VERSION "Vinfast Single Pack DBC V0.1"

NS_ :

BS_:

BU_: BSS_SLAVE PACK
VAL_TABLE_ bms_rentalinfoPackType 2 "Pack D1" 1 "Pack E1" 0 "TBD" ;
VAL_TABLE_ bms_rentalinfoTBD1 2 "1.2kwh" 1 "1.9kwh" 0 "TBD" ;
VAL_TABLE_ bms_resultCheckScuSn 1 "PASS" 0 "FAIL" ;

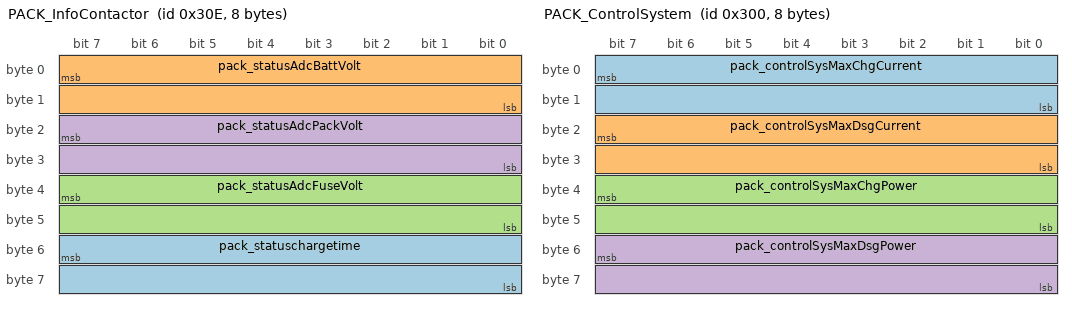
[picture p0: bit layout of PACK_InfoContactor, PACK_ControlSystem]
BO_ 782 PACK_InfoContactor: 8 PACK
 SG_ pack_statuschargetime : 55|16@0+ (1,0) [0|65535] ""  BSS_SLAVE
 SG_ pack_statusAdcBattVolt : 7|16@0+ (0.002,0) [0|131.07] "V"  BSS_SLAVE
 SG_ pack_statusAdcFuseVolt : 39|16@0+ (0.002,0) [0|131.07] "V"  BSS_SLAVE
 SG_ pack_statusAdcPackVolt : 23|16@0+ (0.002,0) [0|131.07] "V"  BSS_SLAVE

BO_ 2 PACK_ISO_Message: 8 PACK
 SG_ pack_iso_signal : 7|64@0+ (1,0) [0|1.84467440737096E+019] ""  BSS_SLAVE

BO_ 768 PACK_ControlSystem: 8 PACK
 SG_ pack_controlSysMaxChgCurrent : 7|16@0- (0.02,0) [-655|655] "A"  BSS_SLAVE
 SG_ pack_controlSysMaxDsgCurrent : 23|16@0- (0.02,0) [-655|655] "A"  BSS_SLAVE
 SG_ pack_controlSysMaxChgPower : 39|16@0- (1,0) [-32767|32767] "W"  BSS_SLAVE
 SG_ pack_controlSysMaxDsgPower : 55|16@0- (1,0) [-32767|32767] "W"  BSS_SLAVE

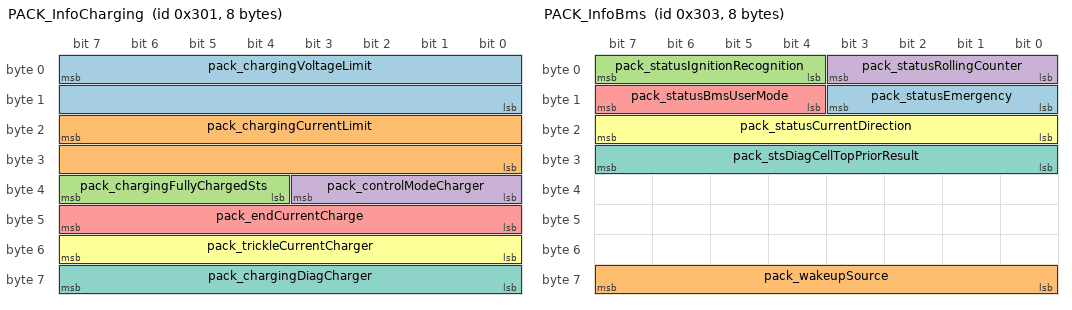
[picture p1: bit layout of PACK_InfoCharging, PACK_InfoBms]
BO_ 769 PACK_InfoCharging: 8 PACK
 SG_ pack_chargingVoltageLimit : 7|16@0+ (0.002,0) [0|131.07] "V"  BSS_SLAVE
 SG_ pack_chargingCurrentLimit : 23|16@0- (0.02,0) [-655|655] "A"  BSS_SLAVE
 SG_ pack_chargingFullyChargedSts : 39|4@0+ (1,0) [0|15] ""  BSS_SLAVE
 SG_ pack_controlModeCharger : 35|4@0+ (1,0) [0|15] ""  BSS_SLAVE
 SG_ pack_endCurrentCharge : 47|8@0+ (0.01,0) [0|2.55] "A"  BSS_SLAVE
 SG_ pack_trickleCurrentCharger : 55|8@0+ (0.01,0) [0|2.55] "A"  BSS_SLAVE
 SG_ pack_chargingDiagCharger : 63|8@0+ (1,0) [0|255] ""  BSS_SLAVE

BO_ 771 PACK_InfoBms: 8 PACK
 SG_ pack_statusEmergency : 11|4@0+ (1,0) [0|15] "" BSS_SLAVE
 SG_ pack_wakeupSource : 63|8@0+ (1,0) [0|255] ""  BSS_SLAVE
 SG_ pack_statusIgnitionRecognition : 7|4@0+ (1,0) [0|15] ""  BSS_SLAVE
 SG_ pack_statusRollingCounter : 3|4@0+ (1,0) [0|15] ""  BSS_SLAVE
 SG_ pack_statusBmsUserMode : 15|4@0+ (1,0) [0|15] ""  BSS_SLAVE
 SG_ pack_statusCurrentDirection : 23|8@0+ (1,0) [0|255] ""  BSS_SLAVE
 SG_ pack_stsDiagCellTopPriorResult : 31|8@0+ (1,0) [0|255] ""  BSS_SLAVE

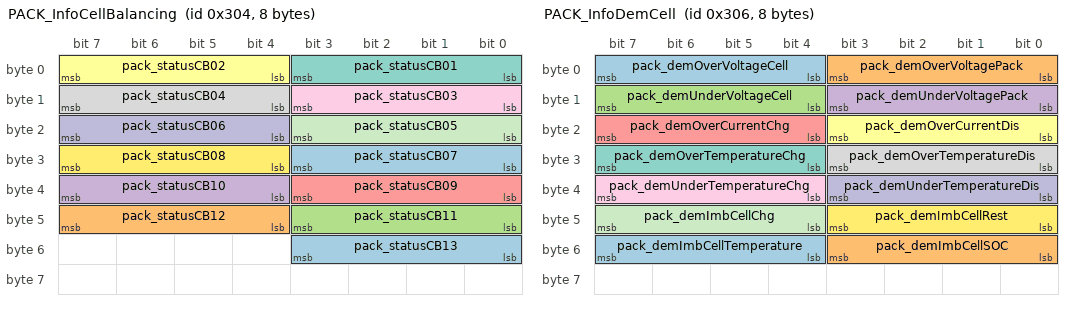
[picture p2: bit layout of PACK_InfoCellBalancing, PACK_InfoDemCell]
BO_ 772 PACK_InfoCellBalancing: 8 PACK
 SG_ pack_statusCB13 : 51|4@0+ (1,0) [0|15] ""  BSS_SLAVE
 SG_ pack_statusCB12 : 47|4@0+ (1,0) [0|15] ""  BSS_SLAVE
 SG_ pack_statusCB11 : 43|4@0+ (1,0) [0|15] ""  BSS_SLAVE
 SG_ pack_statusCB10 : 39|4@0+ (1,0) [0|15] ""  BSS_SLAVE
 SG_ pack_statusCB09 : 35|4@0+ (1,0) [0|15] ""  BSS_SLAVE
 SG_ pack_statusCB02 : 7|4@0+ (1,0) [0|15] ""  BSS_SLAVE
 SG_ pack_statusCB01 : 3|4@0+ (1,0) [0|15] ""  BSS_SLAVE
 SG_ pack_statusCB04 : 15|4@0+ (1,0) [0|15] ""  BSS_SLAVE
 SG_ pack_statusCB03 : 11|4@0+ (1,0) [0|15] ""  BSS_SLAVE
 SG_ pack_statusCB06 : 23|4@0+ (1,0) [0|15] ""  BSS_SLAVE
 SG_ pack_statusCB05 : 19|4@0+ (1,0) [0|15] ""  BSS_SLAVE
 SG_ pack_statusCB08 : 31|4@0+ (1,0) [0|15] ""  BSS_SLAVE
 SG_ pack_statusCB07 : 27|4@0+ (1,0) [0|15] ""  BSS_SLAVE

BO_ 774 PACK_InfoDemCell: 8 PACK
 SG_ pack_demOverVoltageCell : 7|4@0+ (1,0) [0|15] ""  BSS_SLAVE
 SG_ pack_demOverVoltagePack : 3|4@0+ (1,0) [0|15] ""  BSS_SLAVE
 SG_ pack_demUnderVoltageCell : 15|4@0+ (1,0) [0|15] ""  BSS_SLAVE
 SG_ pack_demUnderVoltagePack : 11|4@0+ (1,0) [0|15] ""  BSS_SLAVE
 SG_ pack_demOverCurrentChg : 23|4@0+ (1,0) [0|15] ""  BSS_SLAVE
 SG_ pack_demOverCurrentDis : 19|4@0+ (1,0) [0|15] ""  BSS_SLAVE
 SG_ pack_demOverTemperatureChg : 31|4@0+ (1,0) [0|15] ""  BSS_SLAVE
 SG_ pack_demOverTemperatureDis : 27|4@0+ (1,0) [0|15] ""  BSS_SLAVE
 SG_ pack_demUnderTemperatureChg : 39|4@0+ (1,0) [0|15] ""  BSS_SLAVE
 SG_ pack_demUnderTemperatureDis : 35|4@0+ (1,0) [0|15] ""  BSS_SLAVE
 SG_ pack_demImbCellChg : 47|4@0+ (1,0) [0|15] ""  BSS_SLAVE
 SG_ pack_demImbCellRest : 43|4@0+ (1,0) [0|15] ""  BSS_SLAVE
 SG_ pack_demImbCellTemperature : 55|4@0+ (1,0) [0|15] ""  BSS_SLAVE
 SG_ pack_demImbCellSOC : 51|4@0+ (1,0) [0|15] ""  BSS_SLAVE

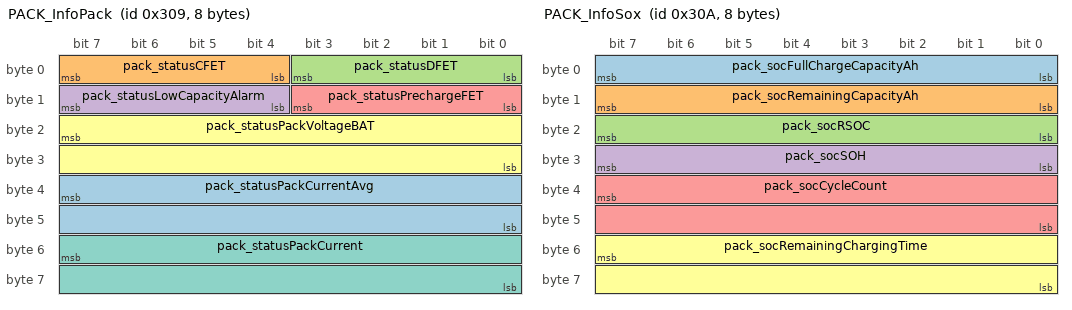
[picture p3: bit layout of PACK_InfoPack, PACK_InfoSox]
BO_ 777 PACK_InfoPack: 8 PACK
 SG_ pack_statusPackCurrentAvg : 39|16@0- (0.02,0) [-655.36|655.34] "A"  BSS_SLAVE
 SG_ pack_statusCFET : 7|4@0+ (1,0) [0|15] ""  BSS_SLAVE
 SG_ pack_statusDFET : 3|4@0+ (1,0) [0|15] ""  BSS_SLAVE
 SG_ pack_statusLowCapacityAlarm : 15|4@0+ (1,0) [0|15] ""  BSS_SLAVE
 SG_ pack_statusPrechargeFET : 11|4@0+ (1,0) [0|15] ""  BSS_SLAVE
 SG_ pack_statusPackVoltageBAT : 23|16@0+ (0.002,0) [0|131.07] "V"  BSS_SLAVE
 SG_ pack_statusPackCurrent : 55|16@0- (0.02,0) [-655.36|655.34] "A"  BSS_SLAVE

BO_ 778 PACK_InfoSox: 8 PACK
 SG_ pack_socFullChargeCapacityAh : 7|8@0+ (0.4,0) [0|76.5] "Ah"  BSS_SLAVE
 SG_ pack_socRemainingCapacityAh : 15|8@0+ (0.4,0) [0|102] "Ah"  BSS_SLAVE
 SG_ pack_socRSOC : 23|8@0+ (1,0) [0|255] "%"  BSS_SLAVE
 SG_ pack_socSOH : 31|8@0+ (1,0) [0|255] "%"  BSS_SLAVE
 SG_ pack_socCycleCount : 39|16@0+ (1,0) [0|65535] ""  BSS_SLAVE
 SG_ pack_socRemainingChargingTime : 55|16@0+ (1,0) [0|65535] "min"  BSS_SLAVE

BO_ 779 PACK_InfoAccumDsgChgCapacity: 8 PACK
 SG_ pack_AccumChargeCapacityAh : 7|32@0+ (1,0) [0|4294967295] "Ah"  BSS_SLAVE
 SG_ pack_AccumDischargeCapacityAh : 39|32@0+ (1,0) [0|4294967295] "Ah"  BSS_SLAVE

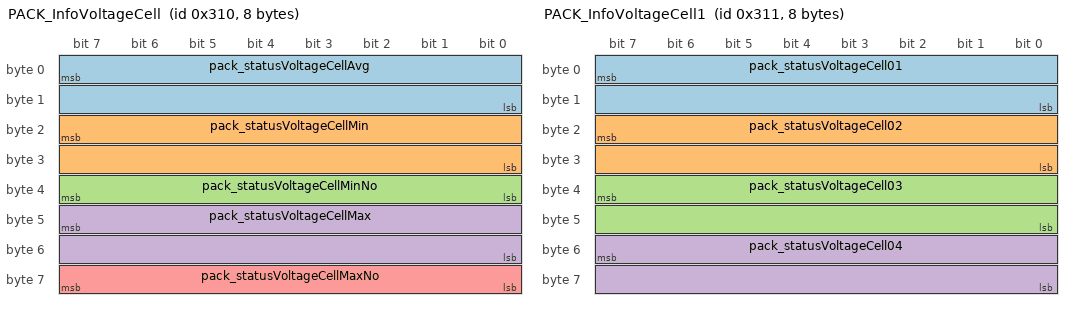
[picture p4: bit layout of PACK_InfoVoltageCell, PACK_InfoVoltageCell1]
BO_ 784 PACK_InfoVoltageCell: 8 PACK
 SG_ pack_statusVoltageCellAvg : 7|16@0+ (0.0001,0) [0|6.5535] "V"  BSS_SLAVE
 SG_ pack_statusVoltageCellMin : 23|16@0+ (0.0001,0) [0|6.5535] "V"  BSS_SLAVE
 SG_ pack_statusVoltageCellMinNo : 39|8@0+ (1,0) [0|255] "Bank"  BSS_SLAVE
 SG_ pack_statusVoltageCellMax : 47|16@0+ (0.0001,0) [0|6.5535] "V"  BSS_SLAVE
 SG_ pack_statusVoltageCellMaxNo : 63|8@0+ (1,0) [0|255] "Bank"  BSS_SLAVE

BO_ 785 PACK_InfoVoltageCell1: 8 PACK
 SG_ pack_statusVoltageCell01 : 7|16@0+ (0.0001,0) [0|6.5535] "V"  BSS_SLAVE
 SG_ pack_statusVoltageCell02 : 23|16@0+ (0.0001,0) [0|6.5535] "V"  BSS_SLAVE
 SG_ pack_statusVoltageCell03 : 39|16@0+ (0.0001,0) [0|6.5535] "V"  BSS_SLAVE
 SG_ pack_statusVoltageCell04 : 55|16@0+ (0.0001,0) [0|6.5535] "V"  BSS_SLAVE

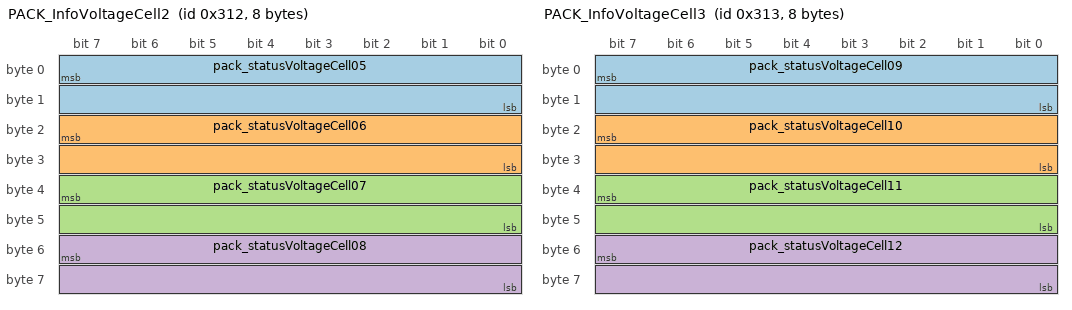
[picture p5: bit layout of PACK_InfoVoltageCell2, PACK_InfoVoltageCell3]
BO_ 786 PACK_InfoVoltageCell2: 8 PACK
 SG_ pack_statusVoltageCell05 : 7|16@0+ (0.0001,0) [0|6.5535] "V"  BSS_SLAVE
 SG_ pack_statusVoltageCell06 : 23|16@0+ (0.0001,0) [0|6.5535] "V"  BSS_SLAVE
 SG_ pack_statusVoltageCell07 : 39|16@0+ (0.0001,0) [0|6.5535] "V"  BSS_SLAVE
 SG_ pack_statusVoltageCell08 : 55|16@0+ (0.0001,0) [0|6.5535] "V"  BSS_SLAVE

BO_ 787 PACK_InfoVoltageCell3: 8 PACK
 SG_ pack_statusVoltageCell09 : 7|16@0+ (0.0001,0) [0|6.5535] "V"  BSS_SLAVE
 SG_ pack_statusVoltageCell10 : 23|16@0+ (0.0001,0) [0|6.5535] "V"  BSS_SLAVE
 SG_ pack_statusVoltageCell11 : 39|16@0+ (0.0001,0) [0|6.5535] "V"  BSS_SLAVE
 SG_ pack_statusVoltageCell12 : 55|16@0+ (0.0001,0) [0|6.5535] "V"  BSS_SLAVE

BO_ 788 PACK_InfoVoltageCell4: 2 PACK
 SG_ pack_statusVoltageCell13 : 7|16@0+ (0.0001,0) [0|6.5535] "V"  BSS_SLAVE

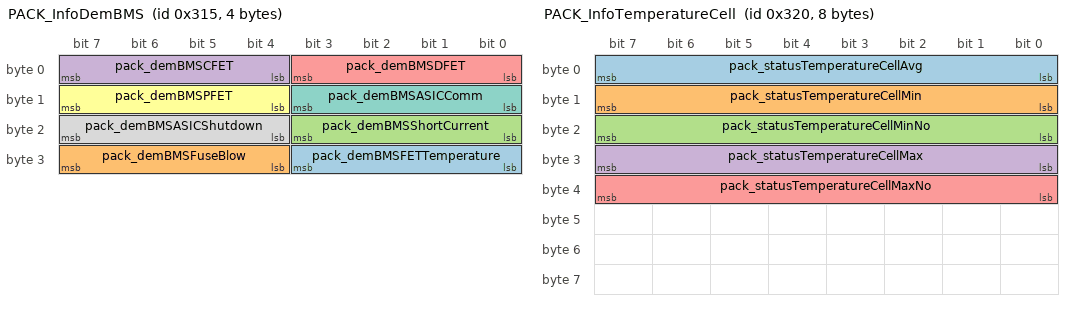
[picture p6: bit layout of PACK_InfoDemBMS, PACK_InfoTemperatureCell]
BO_ 789 PACK_InfoDemBMS: 4 PACK
 SG_ pack_demBMSFETTemperature : 27|4@0+ (1,0) [0|15] ""  BSS_SLAVE
 SG_ pack_demBMSFuseBlow : 31|4@0+ (1,0) [0|15] ""  BSS_SLAVE
 SG_ pack_demBMSShortCurrent : 19|4@0+ (1,0) [0|15] ""  BSS_SLAVE
 SG_ pack_demBMSCFET : 7|4@0+ (1,0) [0|15] ""  BSS_SLAVE
 SG_ pack_demBMSDFET : 3|4@0+ (1,0) [0|15] ""  BSS_SLAVE
 SG_ pack_demBMSPFET : 15|4@0+ (1,0) [0|15] ""  BSS_SLAVE
 SG_ pack_demBMSASICComm : 11|4@0+ (1,0) [0|15] ""  BSS_SLAVE
 SG_ pack_demBMSASICShutdown : 23|4@0+ (1,0) [0|15] ""  BSS_SLAVE

BO_ 800 PACK_InfoTemperatureCell: 8 PACK
 SG_ pack_statusTemperatureCellAvg : 7|8@0- (1,0) [-127|127] "��"  BSS_SLAVE
 SG_ pack_statusTemperatureCellMin : 15|8@0- (1,0) [-127|127] "��"  BSS_SLAVE
 SG_ pack_statusTemperatureCellMinNo : 23|8@0+ (1,0) [0|255] "Th"  BSS_SLAVE
 SG_ pack_statusTemperatureCellMax : 31|8@0- (1,0) [-127|127] "��"  BSS_SLAVE
 SG_ pack_statusTemperatureCellMaxNo : 39|8@0+ (1,0) [0|255] "Th"  BSS_SLAVE

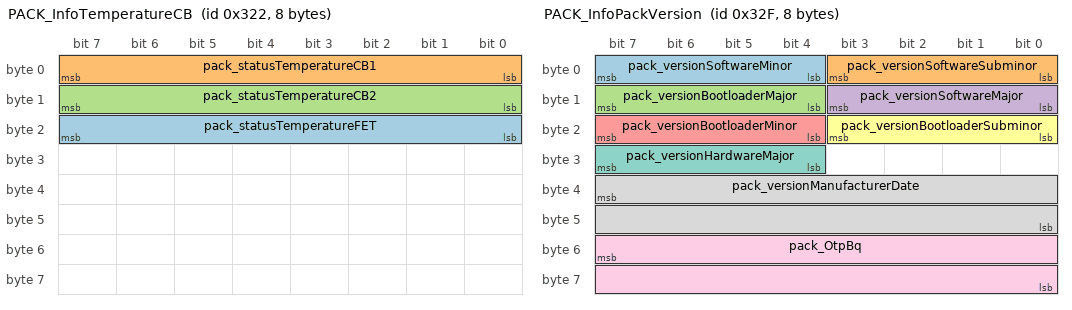
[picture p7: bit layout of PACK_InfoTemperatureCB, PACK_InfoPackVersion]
BO_ 802 PACK_InfoTemperatureCB: 8 PACK
 SG_ pack_statusTemperatureFET : 23|8@0- (1,0) [-127|127] "��"  BSS_SLAVE
 SG_ pack_statusTemperatureCB1 : 7|8@0- (1,0) [-127|127] "��"  BSS_SLAVE
 SG_ pack_statusTemperatureCB2 : 15|8@0- (1,0) [-127|127] "��"  BSS_SLAVE

BO_ 815 PACK_InfoPackVersion: 8 PACK
 SG_ pack_versionSoftwareMinor : 7|4@0+ (1,0) [0|15] ""  BSS_SLAVE
 SG_ pack_versionSoftwareSubminor : 3|4@0+ (1,0) [0|15] ""  BSS_SLAVE
 SG_ pack_versionBootloaderMajor : 15|4@0+ (1,0) [0|15] ""  BSS_SLAVE
 SG_ pack_versionSoftwareMajor : 11|4@0+ (1,0) [0|15] ""  BSS_SLAVE
 SG_ pack_versionBootloaderMinor : 23|4@0+ (1,0) [0|15] ""  BSS_SLAVE
 SG_ pack_versionBootloaderSubminor : 19|4@0+ (1,0) [0|15] ""  BSS_SLAVE
 SG_ pack_versionHardwareMajor : 31|4@0+ (1,0) [0|15] ""  BSS_SLAVE
 SG_ pack_versionManufacturerDate : 39|16@0+ (1,0) [0|65535] ""  BSS_SLAVE
 SG_ pack_OtpBq : 55|16@0+ (1,0) [0|65535] ""  BSS_SLAVE

CM_ BU_ PACK "48V Battery Module";
CM_ BO_ 782 "Status of battery pack.";
CM_ BO_ 2 "Message use for ISO15765 of  BLG";
CM_ BO_ 768 "This message is used by the battery to control the system.";
CM_ BO_ 769 "Status of Chariging status";
CM_ BO_ 771 "Status of BMS.";
CM_ BO_ 772 "Operating state of the cell balancing circuit of the battery pack.";
CM_ BO_ 774 "Diagnostic information of the Cell.";
CM_ BO_ 777 "Status of battery pack.";
CM_ BO_ 778 "SOH, RSOC, Cycle count, ... of battery pack.";
CM_ BO_ 779 "Accumulated Discharge/Charge Capacity";
CM_ BO_ 784 "Cell voltage.";
CM_ BO_ 785 "Cell voltage.";
CM_ BO_ 786 "Cell voltage.";
CM_ BO_ 787 "Cell voltage.";
CM_ BO_ 788 "Cell voltage.";
CM_ BO_ 789 "Diagnostic information of the BMS.";
CM_ BO_ 800 "Cell temperature inside the battery pack.";
CM_ BO_ 802 "Temperature of the components in the battery pack.";
CM_ BO_ 815 "Version of battery pack or product information";
CM_ SG_ 782 pack_statusAdcBattVolt "Min) Sum of all series cell voltage.";
CM_ SG_ 782 pack_statusAdcFuseVolt "Min) Sum of all series cell voltage.";
CM_ SG_ 782 pack_statusAdcPackVolt "Min) Sum of all series cell voltage.";
CM_ SG_ 2 pack_iso_signal "Signal use for ISO15765 of BMS0";
CM_ SG_ 768 pack_controlSysMaxChgCurrent "sum) System Available max charging current value.";
CM_ SG_ 768 pack_controlSysMaxDsgCurrent "sum) System Available max discharging current value.";
CM_ SG_ 768 pack_controlSysMaxChgPower "sum) System Available max charging power value.";
CM_ SG_ 768 pack_controlSysMaxDsgPower "sum) System Available max discharging power value.";
CM_ SG_ 769 pack_chargingVoltageLimit "Min) Voltage limitation value for charging (in case of fault, this value will be zero)";
CM_ SG_ 769 pack_chargingCurrentLimit "Min) Current limitation value for charging (in case of fault, this value will be zero)";
CM_ SG_ 769 pack_chargingFullyChargedSts "Or) Fully charged status.";
CM_ SG_ 769 pack_controlModeCharger "0:Charge_OFF 1:Charge_Normal 2:Trickle_mode";
CM_ SG_ 769 pack_endCurrentCharge "BMS send end charge current to charger stop charge";
CM_ SG_ 769 pack_trickleCurrentCharger "BMS send max Trickle current to limit current in Trickle mode";
CM_ SG_ 769 pack_chargingDiagCharger "Or) DiagCharger";
CM_ SG_ 771 pack_statusEmergency "Sel) User mode of the battery pack.";
CM_ SG_ 771 pack_statusIgnitionRecognition "And) Status that BMS recognizes ignition pin";
CM_ SG_ 771 pack_statusRollingCounter "Master) 0,1,2,3 -> 0,1,2,3.   It is rolling count means to BMS processing is well.  It will stop counting, if BMS processing gets stuck";
CM_ SG_ 771 pack_statusBmsUserMode "Sel) User mode of the battery pack.";
CM_ SG_ 771 pack_statusCurrentDirection "Sel) Current(Amps) Direction";
CM_ SG_ 771 pack_stsDiagCellTopPriorResult "Max) Most Severe Cell Diagnosis Result based on priority of diagnosis item and diagnosis level.";
CM_ SG_ 772 pack_statusCB13 "Or) Status of cell balancing circuit.";
CM_ SG_ 772 pack_statusCB12 "Or) Status of cell balancing circuit.";
CM_ SG_ 772 pack_statusCB11 "Or) Status of cell balancing circuit.";
CM_ SG_ 772 pack_statusCB10 "Or) Status of cell balancing circuit.";
CM_ SG_ 772 pack_statusCB09 "Or) Status of cell balancing circuit.";
CM_ SG_ 772 pack_statusCB02 "Or) Status of cell balancing circuit.";
CM_ SG_ 772 pack_statusCB01 "Or) Status of cell balancing circuit.";
CM_ SG_ 772 pack_statusCB04 "Or) Status of cell balancing circuit.";
CM_ SG_ 772 pack_statusCB03 "Or) Status of cell balancing circuit.";
CM_ SG_ 772 pack_statusCB06 "Or) Status of cell balancing circuit.";
CM_ SG_ 772 pack_statusCB05 "Or) Status of cell balancing circuit.";
CM_ SG_ 772 pack_statusCB08 "Or) Status of cell balancing circuit.";
CM_ SG_ 772 pack_statusCB07 "Or) Status of cell balancing circuit.";
CM_ SG_ 774 pack_demOverVoltageCell "Max) Diagnosis - Over voltage Cell.";
CM_ SG_ 774 pack_demOverVoltagePack "Max) Diagnosis - Over voltage Pack.";
CM_ SG_ 774 pack_demUnderVoltageCell "Max) Diagnosis - Under voltage Cell.";
CM_ SG_ 774 pack_demUnderVoltagePack "Max) Diagnosis - Under voltage Pack.";
CM_ SG_ 774 pack_demOverCurrentChg "Max) Diagnosis - Over charge current.";
CM_ SG_ 774 pack_demOverCurrentDis "Max) Diagnosis - Over discharge current.";
CM_ SG_ 774 pack_demOverTemperatureChg "Max) Diagnosis - Over temperature in charging.";
CM_ SG_ 774 pack_demOverTemperatureDis "Max) Diagnosis - Over temperature in discharging.";
CM_ SG_ 774 pack_demUnderTemperatureChg "Max) Diagnosis - Under temperature in charging.";
CM_ SG_ 774 pack_demUnderTemperatureDis "Max) Diagnosis - Under temperature in discharging.";
CM_ SG_ 774 pack_demImbCellChg "Max) Diagnosis - Cell voltage imbalance in Charging.";
CM_ SG_ 774 pack_demImbCellRest "Max) Diagnosis - Cell voltage imbalance in Rest.";
CM_ SG_ 774 pack_demImbCellTemperature "Max) Diagnosis - Imbalance Cell Temperature";
CM_ SG_ 774 pack_demImbCellSOC "Max) Diagnosis - Cell SOC imbalance.";
CM_ SG_ 777 pack_statusPackCurrentAvg "Sum) Measuring pack current,  charging is positive, discharging is negative.";
CM_ SG_ 777 pack_statusCFET "And) control status of C-FET";
CM_ SG_ 777 pack_statusDFET "And) control status of D-FET";
CM_ SG_ 777 pack_statusLowCapacityAlarm "Or) Alarm - Low capacity (SOC < 10%)";
CM_ SG_ 777 pack_statusPrechargeFET "And) control status of Precharge-FET";
CM_ SG_ 777 pack_statusPackVoltageBAT "Min) Sum of all series cell voltage.";
CM_ SG_ 777 pack_statusPackCurrent "Sum) Measuring pack current,  charging is positive, discharging is negative.";
CM_ SG_ 778 pack_socFullChargeCapacityAh "Sum) Full Charge Capacity Ah.";
CM_ SG_ 778 pack_socRemainingCapacityAh "Sum) Remaining Capacity Ah.";
CM_ SG_ 778 pack_socRSOC "Min) Relative State Of Charge.";
CM_ SG_ 778 pack_socSOH "Min) State of health.";
CM_ SG_ 778 pack_socCycleCount "Max) Cycle Count";
CM_ SG_ 778 pack_socRemainingChargingTime "Min) Remaining Charging Time";
CM_ SG_ 779 pack_AccumChargeCapacityAh "Max) Accumulated Charge Capacity(Ah)";
CM_ SG_ 779 pack_AccumDischargeCapacityAh "Max) Accumulated Discharge Capacity(Ah)";
CM_ SG_ 784 pack_statusVoltageCellAvg "Min) Average cell voltage.";
CM_ SG_ 784 pack_statusVoltageCellMin "Min) minimum cell voltage.";
CM_ SG_ 784 pack_statusVoltageCellMinNo "Sel) minimum cell voltage number";
CM_ SG_ 784 pack_statusVoltageCellMax "Max) maximum cell voltage.";
CM_ SG_ 784 pack_statusVoltageCellMaxNo "Sel) maximum cell voltage number";
CM_ SG_ 785 pack_statusVoltageCell01 "Min) Cell voltage.";
CM_ SG_ 785 pack_statusVoltageCell02 "Min) Cell voltage.";
CM_ SG_ 785 pack_statusVoltageCell03 "Min) Cell voltage.";
CM_ SG_ 785 pack_statusVoltageCell04 "Min) Cell voltage.";
CM_ SG_ 786 pack_statusVoltageCell05 "Min) Cell voltage.";
CM_ SG_ 786 pack_statusVoltageCell06 "Min) Cell voltage.";
CM_ SG_ 786 pack_statusVoltageCell07 "Min) Cell voltage.";
CM_ SG_ 786 pack_statusVoltageCell08 "Min) Cell voltage.";
CM_ SG_ 787 pack_statusVoltageCell09 "Min) Cell voltage.";
CM_ SG_ 787 pack_statusVoltageCell10 "Min) Cell voltage.";
CM_ SG_ 787 pack_statusVoltageCell11 "Min) Cell voltage.";
CM_ SG_ 787 pack_statusVoltageCell12 "Min) Cell voltage.";
CM_ SG_ 788 pack_statusVoltageCell13 "Min) Cell voltage.";
CM_ SG_ 789 pack_demBMSFETTemperature "Max) Diagnosis - Pack FET Temperature(Over)";
CM_ SG_ 789 pack_demBMSFuseBlow "Max) Diagnosis - Pack Fuse Blow";
CM_ SG_ 789 pack_demBMSShortCurrent "Max) Diagnosis - Asic Short Current";
CM_ SG_ 789 pack_demBMSCFET "Max) Diagnosis - BMS CFET";
CM_ SG_ 789 pack_demBMSDFET "Max) Diagnosis - BMS DFET";
CM_ SG_ 789 pack_demBMSPFET "Max) Diagnosis - BMS PFET";
CM_ SG_ 789 pack_demBMSASICComm "Max) Diagnosis - BMS ASIC Comm";
CM_ SG_ 789 pack_demBMSASICShutdown "Max) Diagnosis - BMS ASIC Shutdowm";
CM_ SG_ 800 pack_statusTemperatureCellAvg "Avg) Average Temperature - cell.";
CM_ SG_ 800 pack_statusTemperatureCellMin "Min) Minimum Temperature - cell.";
CM_ SG_ 800 pack_statusTemperatureCellMinNo "Sel) Minimum Temperature Number - cell.";
CM_ SG_ 800 pack_statusTemperatureCellMax "Max) Maximum Temperature - cell.";
CM_ SG_ 800 pack_statusTemperatureCellMaxNo "Sel) Maximum Temperature Number - cell.";
CM_ SG_ 802 pack_statusTemperatureFET "Max) Temperature - cell balancing circuit.";
CM_ SG_ 802 pack_statusTemperatureCB1 "Max) Temperature - cell balancing circuit.";
CM_ SG_ 802 pack_statusTemperatureCB2 "Max) Temperature - cell balancing circuit.";
CM_ SG_ 815 pack_versionSoftwareMinor "Min) Version - application_minor";
CM_ SG_ 815 pack_versionSoftwareSubminor "Min) Version - application_subminor";
CM_ SG_ 815 pack_versionBootloaderMajor "Min) Version - bootloader";
CM_ SG_ 815 pack_versionSoftwareMajor "Min) Version - application_major";
CM_ SG_ 815 pack_versionBootloaderMinor "Min) Version - bootloader";
CM_ SG_ 815 pack_versionBootloaderSubminor "Min) Version - bootloader";
CM_ SG_ 815 pack_versionHardwareMajor "Min) Version - BMS HW";
CM_ SG_ 815 pack_versionManufacturerDate "Min) Manufactuer Date";
CM_ SG_ 815 pack_OtpBq "Min) manufacturer serial number per day";
BA_DEF_  "BusECUIdLength" INT 5 6;
BA_DEF_  "BusID" INT 0 255;
BA_DEF_  "BusName" STRING ;
BA_DEF_  "BusType" STRING ;
BA_DEF_  "DBName" STRING ;
BA_DEF_ BO_  "cycleMilliSecs100" INT 0 100;
BA_DEF_ BO_  "GenMsgCycleTime" INT 0 65000;
BA_DEF_ BO_  "GenMsgSendType" ENUM  "Fixed Periodic","Enabled Periodic","NoMsgSendType","Event";
BA_DEF_ BO_  "targetGw" ENUM  "BPG","BGW","IVI","SDCM","ALL";
BA_DEF_ BO_  "transmitMsgRateEthernetMs" ENUM  "10","100","1000";
BA_DEF_ BU_  "NmDefaultAddress" ENUM  "USE_PRIMARY_ADDRESS","USE_SECONDARY_ADDRESS";
BA_DEF_ BU_  "NodeLayerModules" STRING ;
BA_DEF_ SG_  "SNARequired" ENUM  "Required","NotRequired";
BA_DEF_DEF_  "BusECUIdLength" 5;
BA_DEF_DEF_  "BusID" 0;
BA_DEF_DEF_  "BusName" "AuxBattery";
BA_DEF_DEF_  "BusType" "CAN";
BA_DEF_DEF_  "DBName" "";
BA_DEF_DEF_  "cycleMilliSecs100" 100;
BA_DEF_DEF_  "GenMsgCycleTime" 0;
BA_DEF_DEF_  "GenMsgSendType" "NoMsgSendType";
BA_DEF_DEF_  "targetGw" "ALL";
BA_DEF_DEF_  "transmitMsgRateEthernetMs" "1000";
BA_DEF_DEF_  "NmDefaultAddress" "USE_PRIMARY_ADDRESS";
BA_DEF_DEF_  "NodeLayerModules" "CANoeILNLVector.dll";
BA_DEF_DEF_  "SNARequired" "Required";
BA_ "BusName" "SinglePack";
BA_ "BusID" 136;
BA_ "DBName" "SinglePack";
BA_ "GenMsgSendType" BO_ 782 0;
BA_ "GenMsgCycleTime" BO_ 782 150;
BA_ "GenMsgCycleTime" BO_ 768 150;
BA_ "GenMsgSendType" BO_ 768 0;
BA_ "GenMsgCycleTime" BO_ 769 1000;
BA_ "GenMsgSendType" BO_ 769 0;
BA_ "GenMsgCycleTime" BO_ 771 150;
BA_ "GenMsgSendType" BO_ 771 0;
BA_ "GenMsgCycleTime" BO_ 772 1000;
BA_ "GenMsgSendType" BO_ 772 0;
BA_ "GenMsgCycleTime" BO_ 774 150;
BA_ "GenMsgSendType" BO_ 774 0;
BA_ "GenMsgCycleTime" BO_ 777 150;
BA_ "GenMsgSendType" BO_ 777 0;
BA_ "GenMsgCycleTime" BO_ 778 1000;
BA_ "GenMsgSendType" BO_ 778 0;
BA_ "GenMsgCycleTime" BO_ 779 3000;
BA_ "GenMsgSendType" BO_ 779 0;
BA_ "GenMsgCycleTime" BO_ 784 500;
BA_ "GenMsgSendType" BO_ 784 0;
BA_ "GenMsgCycleTime" BO_ 785 500;
BA_ "GenMsgSendType" BO_ 785 0;
BA_ "GenMsgCycleTime" BO_ 786 500;
BA_ "GenMsgSendType" BO_ 786 0;
BA_ "GenMsgCycleTime" BO_ 787 500;
BA_ "GenMsgSendType" BO_ 787 0;
BA_ "GenMsgCycleTime" BO_ 788 500;
BA_ "GenMsgSendType" BO_ 788 0;
BA_ "GenMsgCycleTime" BO_ 789 500;
BA_ "GenMsgSendType" BO_ 789 0;
BA_ "GenMsgCycleTime" BO_ 800 1000;
BA_ "GenMsgSendType" BO_ 800 0;
BA_ "GenMsgCycleTime" BO_ 802 500;
BA_ "GenMsgSendType" BO_ 802 0;
BA_ "GenMsgCycleTime" BO_ 815 1000;
BA_ "GenMsgSendType" BO_ 815 0;
VAL_ 769 pack_chargingFullyChargedSts 0 "N/A" 1 "Charging" 2 "Fully Charged" ;
VAL_ 771 pack_wakeupSource 1 "Wake up by BMS SW" 0 "Wake up by RTC" ;
VAL_ 771 pack_statusIgnitionRecognition 0 "Low" 1 "High" ;
VAL_ 771 pack_statusBmsUserMode 0 "Standby Mode" 1 "Working Mode" ;
VAL_ 771 pack_statusCurrentDirection 0 "Rest" 1 "Charging" 2 "Discharging" ;
VAL_ 772 pack_statusCB13 0 "Off" 1 "On" ;
VAL_ 772 pack_statusCB12 0 "Off" 1 "On" ;
VAL_ 772 pack_statusCB11 0 "Off" 1 "On" ;
VAL_ 772 pack_statusCB10 0 "Off" 1 "On" ;
VAL_ 772 pack_statusCB09 0 "Off" 1 "On" ;
VAL_ 772 pack_statusCB02 0 "Off" 1 "On" ;
VAL_ 772 pack_statusCB01 0 "Off" 1 "On" ;
VAL_ 772 pack_statusCB04 0 "Off" 1 "On" ;
VAL_ 772 pack_statusCB03 0 "Off" 1 "On" ;
VAL_ 772 pack_statusCB06 0 "Off" 1 "On" ;
VAL_ 772 pack_statusCB05 0 "Off" 1 "On" ;
VAL_ 772 pack_statusCB08 0 "Off" 1 "On" ;
VAL_ 772 pack_statusCB07 0 "Off" 1 "On" ;
VAL_ 774 pack_demOverVoltageCell 0 "Normal" 1 "Warning1" 2 "Warning2" 3 "Fault" 4 "Failure" 5 "RSVD5" 6 "RSVD6" 7 "RSVD7" ;
VAL_ 774 pack_demOverVoltagePack 0 "Normal" 1 "Warning1" 2 "Warning2" 3 "Fault" 4 "Failure" 5 "RSVD5" 6 "RSVD6" 7 "RSVD7" ;
VAL_ 774 pack_demUnderVoltageCell 0 "Normal" 1 "Warning1" 2 "Warning2" 3 "Fault" 4 "Failure" 5 "RSVD5" 6 "RSVD6" 7 "RSVD7" ;
VAL_ 774 pack_demUnderVoltagePack 0 "Normal" 1 "Warning1" 2 "Warning2" 3 "Fault" 4 "Failure" 5 "RSVD5" 6 "RSVD6" 7 "RSVD7" ;
VAL_ 774 pack_demOverCurrentChg 0 "Normal" 1 "Warning1" 2 "Warning2" 3 "Fault" 4 "Failure" 5 "RSVD5" 6 "RSVD6" 7 "RSVD7" ;
VAL_ 774 pack_demOverCurrentDis 0 "Normal" 1 "Warning1" 2 "Warning2" 3 "Fault" 4 "Failure" 5 "RSVD5" 6 "RSVD6" 7 "RSVD7" ;
VAL_ 774 pack_demOverTemperatureChg 0 "Normal" 1 "Warning1" 2 "Warning2" 3 "Fault" 4 "Failure" 5 "RSVD5" 6 "RSVD6" 7 "RSVD7" ;
VAL_ 774 pack_demOverTemperatureDis 0 "Normal" 1 "Warning1" 2 "Warning2" 3 "Fault" 4 "Failure" 5 "RSVD5" 6 "RSVD6" 7 "RSVD7" ;
VAL_ 774 pack_demUnderTemperatureChg 0 "Normal" 1 "Warning1" 2 "Warning2" 3 "Fault" 4 "Failure" 5 "RSVD5" 6 "RSVD6" 7 "RSVD7" ;
VAL_ 774 pack_demUnderTemperatureDis 0 "Normal" 1 "Warning1" 2 "Warning2" 3 "Fault" 4 "Failure" 5 "RSVD5" 6 "RSVD6" 7 "RSVD7" ;
VAL_ 774 pack_demImbCellChg 0 "Normal" 1 "Warning1" 2 "Warning2" 3 "Fault" 4 "Failure" 5 "RSVD5" 6 "RSVD6" 7 "RSVD7" ;
VAL_ 774 pack_demImbCellRest 0 "Normal" 1 "Warning1" 2 "Warning2" 3 "Fault" 4 "Failure" 5 "RSVD5" 6 "RSVD6" 7 "RSVD7" ;
VAL_ 774 pack_demImbCellTemperature 0 "Normal" 1 "Warning1" 2 "Warning2" 3 "Fault" 4 "Failure" 5 "RSVD5" 6 "RSVD6" 7 "RSVD7" ;
VAL_ 774 pack_demImbCellSOC 0 "Normal" 1 "Warning1" 2 "Warning2" 3 "Fault" 4 "Failure" 5 "RSVD5" 6 "RSVD6" 7 "RSVD7" ;
VAL_ 777 pack_statusCFET 0 "Off" 1 "On" 2 "RSVD1" 3 "RSVD2" ;
VAL_ 777 pack_statusDFET 0 "Off" 1 "On" 2 "RSVD1" 3 "RSVD2" ;
VAL_ 777 pack_statusLowCapacityAlarm 0 "Clear" 1 "Set" 2 "RSVD1" 3 "RSVD2" ;
VAL_ 777 pack_statusPrechargeFET 0 "Off" 1 "On" 2 "RSVD1" 3 "RSVD2" ;
VAL_ 789 pack_demBMSFETTemperature 0 "Normal" 3 "Fault" ;
VAL_ 789 pack_demBMSFuseBlow 0 "Normal" 3 "Fault" ;
VAL_ 789 pack_demBMSShortCurrent 0 "Normal" 3 "Fault" ;
VAL_ 789 pack_demBMSCFET 0 "Normal" 3 "Fault" ;
VAL_ 789 pack_demBMSDFET 0 "Normal" 3 "Fault" ;
VAL_ 789 pack_demBMSPFET 0 "Normal" 3 "Fault" ;
VAL_ 789 pack_demBMSASICComm 0 "Normal" 3 "Fault" ;
VAL_ 789 pack_demBMSASICShutdown 0 "Normal" 3 "Fault" ;
